# MDR1986VE81 register map
Vendor: Milandr; Series: ARMCM4; File version: 2.0
ARM 32-bit Cortex-M4 Microcontroller based device, CPU clock up to 60MHz, etc.
CPU: CM4 r0p0, little endian, MPU, FPU, 3 interrupt priority bits
Registers are 32-bit, read-write, reset 0x0 unless marked. A register's access mark holds for its fields unless they carry their own. Offsets are from the block's base; lines under a group give offsets from that group; [hi:lo] are bit positions; {n}, {i} and the like mark numbered series; 'fields as' and 'values as' point back to an identical list; <NAME> marks a mode.

## Memory map
0x21000000 MDR_ETH1 size 0x3A — Ethernet Control
0x40000000 MDR_RST_CLOCK size 0x1D0 — CLock Control
0x40001000 MDR_BKP size 0x184 — Backup and RTC Control
0x40005000 MDR_ExtBus size 0xA0 — External Bus Controler
0x40006000 MDR_SRAM size 0x28 — OTP_SRAM Memory Control
0x40080000 MDR_PORTA size 0x8C — PORTA
0x40081000 MDR_PORTB size 0x8C — PORTB
0x40082000 MDR_PORTC size 0x8C — PORTC
0x40083000 MDR_PORTD size 0x8C — PORTD
0x40084000 MDR_PORTE size 0x8C — PORTE
0x4008A000 MDR_TIMER1 size 0x90 — TIMER Control
0x4008B000 MDR_TIMER2 size 0x90
0x4008C000 MDR_TIMER3 size 0x90
0x4008D000 MDR_TIMER4 size 0x90
0x40090000 MDR_CAN1 size 0x600 — CAN Control
0x40095000 MDR_SSP1 size 0x28 — Synchronous Serial Port
0x40099000 MDR_UART1 size 0x84 — UART Control
0x4009A000 MDR_UART2 size 0x84
0xE0042000 MDR_DMA size 0x70 — DMA Controler

## MDR_ExtBus — External Bus Controler
Base 0x40005000
0x00 KEY reset 0x3 — Unlock Block registers
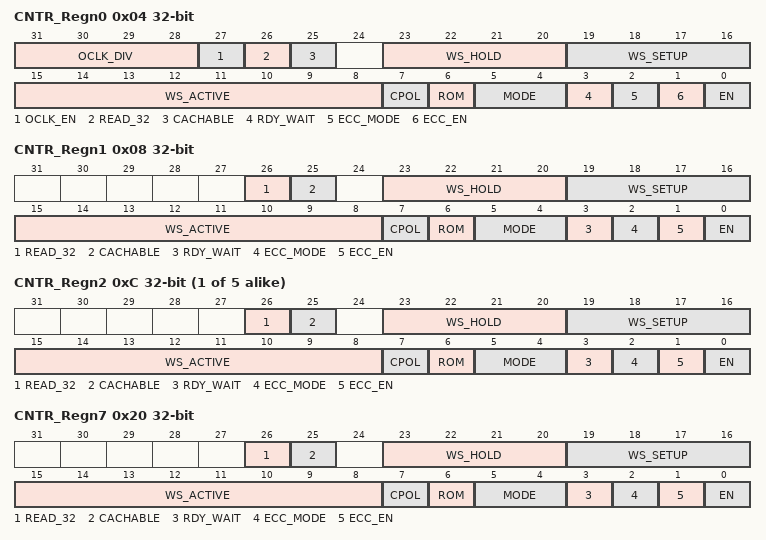
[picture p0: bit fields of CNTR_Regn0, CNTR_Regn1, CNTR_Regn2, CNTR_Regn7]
0x04 CNTR_Regn0 — Region_0 (0x1000_0000) Control
  [31:28] OCLK_DIV — OCLK Prescaller
    {v}=DIV_{v+1} (OCLK Prescaller) (v=0..15)
  [27] OCLK_EN — Enable OCLK output signal
    0=Off (Disable); 1=On (Enable)
  [26] READ_32 — Operate with 32-bit values
    0=Off (Disable); 1=On (Enable)
  [25] CACHABLE — Read Only bus
    0=Off (Disable); 1=On (Enable)
  [23:20] WS_HOLD — Hold phase duration
    {v}=HCLK_{v+1} (Phase Duration) (v=0..15)
  [19:16] WS_SETUP — Setup phase duration
    {v}=HCLK_{v+1} (Phase Duration) (v=0..15)
  [15:8] WS_ACTIVE — Active phase duration
  [7] CPOL — Clock at Active phase
    0=Rise front; 1=Fall front
  [6] ROM — Read Only bus
    0=Off (Disable); 1=On (Enable)
  [5:4] MODE — Data bus width
    0=DataBus_32 (32-bit data bus width); 1=DataBus_16 (16-bit data bus width); 2=DataBus_8 (8-bit data bus width); 3=DataBus_64 (64-bit data bus width)
  [3] RDY_WAIT — Wait for READY signal
    0=Off (Disable); 1=On (Enable)
  [2] ECC_MODE
    0=Parallel (ECC and data in the same addresses); 1=Sequential (ECC in separate address subregion)
  [1] ECC_EN — ECC Enable
    0=Off (Disable); 1=On (Enable)
  [0] EN — Region enable
    0=Off (Disable); 1=On (Enable)
0x08 CNTR_Regn1 — Region_1 (0x1800_0000) Control
  [26] READ_32 — Operate with 32-bit values
    0=Off (Disable); 1=On (Enable)
  [25] CACHABLE — Read Only bus
    0=Off (Disable); 1=On (Enable)
  [23:20] WS_HOLD — Hold phase duration
    {v}=HCLK_{v+1} (Phase Duration) (v=0..15)
  [19:16] WS_SETUP — Setup phase duration
    {v}=HCLK_{v+1} (Phase Duration) (v=0..15)
  [15:8] WS_ACTIVE — Active phase duration
  [7] CPOL — Clock at Active phase
    0=Rise front; 1=Fall front
  [6] ROM — Read Only bus
    0=Off (Disable); 1=On (Enable)
  [5:4] MODE — Data bus width
    values as CNTR_Regn0.MODE
  [3] RDY_WAIT — Wait for READY signal
    0=Off (Disable); 1=On (Enable)
  [2] ECC_MODE
    values as CNTR_Regn0.ECC_MODE
  [1] ECC_EN — ECC Enable
    0=Off (Disable); 1=On (Enable)
  [0] EN — Region enable
    0=Off (Disable); 1=On (Enable)
{0x4+4i} CNTR_Regn{i} (i=2..6) — Region_{i} ({0x4000+0x800*i}_0000) Control
  fields as CNTR_Regn1
0x20 CNTR_Regn7 — Region_7 (0x8000_0000) Control
  fields as CNTR_Regn1
{0x24+4i} ECC_Base{i} (i=0..7) — Base address for sequential ECC
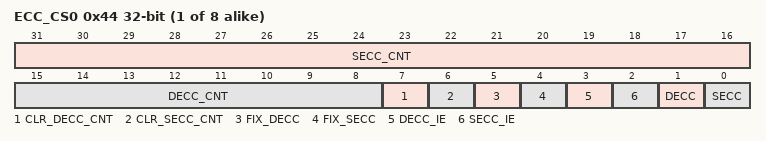
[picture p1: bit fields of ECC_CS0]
{0x44+4i} ECC_CS{i} (i=0..7) — ECC region Control and Status
  [31:16] SECC_CNT — Single error counter
  [15:8] DECC_CNT — Double error counter
  [7] CLR_DECC_CNT — Clear Double error counter
    0=Off (Disable); 1=On (Enable)
  [6] CLR_SECC_CNT — Clear Sigle error counter
    0=Off (Disable); 1=On (Enable)
  [5] FIX_DECC — Log Double Error to regs
    0=Off (Disable); 1=On (Enable)
  [4] FIX_SECC — Log Single Error to regs
    0=Off (Disable); 1=On (Enable)
  [3] DECC_IE — Double error IRQ enable
    0=Off (Disable); 1=On (Enable)
  [2] SECC_IE — Single error IRQ enable
    0=Off (Disable); 1=On (Enable)
  [1] DECC — Double error detected
    0=Off (Disable); 1=On (Enable)
  [0] SECC — Signle error detected
    0=Off (Disable); 1=On (Enable)
0x94 ECC_ADR — Last ECC error address
0x98 ECC_DATA — Last ECC error Data
0x9C ECC_ECC — Last ECC error ECC
  [7:0] ECC — Last wrong ECC
